AUTOSAR XML (schema 4-3-0)
package /Impl_SWC_UDS_ARPkg
  swc implementation Impl_SWC_UDS_type: programming-language=C, sw-version=1.0.0, vendor-id=0, behavior=SWC_UDS_type_IB
    code-descriptors:
      code SRC: artifact-descriptors=autosar-engineering-object={short-label=EngObject, category=SWSRC}
    resource consumption ResourceConsumption
      memory section Mem_SWC_UDS_CODE: size=0, sw-addrmethod=CODE, symbol=CODE
package /SWC_UDS_ARPkg
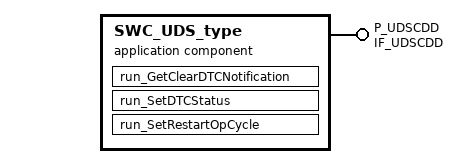
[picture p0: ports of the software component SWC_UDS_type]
  application sw component type SWC_UDS_type
    provide port P_UDSCDD: provided-interface=IF_UDSCDD
    behavior SWC_UDS_type_IB: handle-termination-and-restart=NO-SUPPORT, port-api-option{enable-take-address=false, indirect-api=false, port=P_UDSCDD}
      operation invoked event oie_P_UDSCDD_CSOP_DdmClearDTCNotification: start-on-event=run_GetClearDTCNotification, operation=P_UDSCDD.CSOP_DdmClearDTCNotification
      operation invoked event oie_P_UDSCDD_CSOP_DdmRestartOperationCycle: start-on-event=run_SetRestartOpCycle, operation=P_UDSCDD.CSOP_DdmRestartOperationCycle
      operation invoked event oie_P_UDSCDD_CSOP_SetDTCStatus: start-on-event=run_SetDTCStatus, operation=P_UDSCDD.CSOP_SetDTCStatus
      runnable run_GetClearDTCNotification
      runnable run_SetDTCStatus
      runnable run_SetRestartOpCycle
